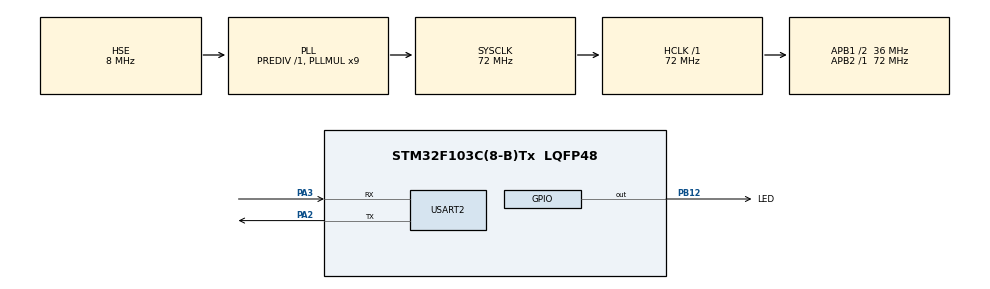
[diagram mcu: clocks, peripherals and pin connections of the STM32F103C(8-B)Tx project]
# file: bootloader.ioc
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IWDG.Prescaler=IWDG_PRESCALER_16
IWDG.Reload=2499
Mcu.Family=STM32F1
Mcu.Name=STM32F103C(8-B)Tx
Mcu.Package=LQFP48
NVIC.PriorityGroup=NVIC_PRIORITYGROUP_4
NVIC.USART2_IRQn=true\:0\:0\:false\:false\:true\:true\:true\:true
PA13.Mode=Serial_Wire
PA13.Signal=SYS_JTMS-SWDIO
PA14.Mode=Serial_Wire
PA14.Signal=SYS_JTCK-SWCLK
PA2.Mode=Asynchronous
PA2.Signal=USART2_TX
PA3.Mode=Asynchronous
PA3.Signal=USART2_RX
PB12.GPIO_Label=LED
PB12.PinState=GPIO_PIN_SET
PB12.Signal=GPIO_Output
PD0-OSC_IN.Mode=HSE-External-Oscillator
PD0-OSC_IN.Signal=RCC_OSC_IN
PD1-OSC_OUT.Mode=HSE-External-Oscillator
PD1-OSC_OUT.Signal=RCC_OSC_OUT
ProjectManager.HeapSize=0x200
ProjectManager.StackSize=0x400
ProjectManager.TargetToolchain=MDK-ARM V5.32
RCC.AHBFreq_Value=72000000
RCC.APB1CLKDivider=RCC_HCLK_DIV2
RCC.APB1Freq_Value=36000000
RCC.APB1TimFreq_Value=72000000
RCC.APB2Freq_Value=72000000
RCC.APB2TimFreq_Value=72000000
RCC.HCLKFreq_Value=72000000
RCC.PLLMUL=RCC_PLL_MUL9
RCC.PLLSourceVirtual=RCC_PLLSOURCE_HSE
RCC.SYSCLKFreq_VALUE=72000000
RCC.SYSCLKSource=RCC_SYSCLKSOURCE_PLLCLK
RCC.USBFreq_Value=72000000
TIM1.Period=1000-1
TIM1.Prescaler=7200-1
USART2.VirtualMode=VM_ASYNC
VP_CRC_VS_CRC.Mode=CRC_Activate
VP_IWDG_VS_IWDG.Mode=IWDG_Activate
VP_TIM1_VS_ClockSourceINT.Mode=Internal
board=custom

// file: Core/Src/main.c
/* USER CODE BEGIN Header */
/**
  ******************************************************************************
  * @file           : main.c
  * @brief          : Main program body
  ******************************************************************************
  * @attention
  *
  * Copyright (c) 2026 STMicroelectronics.
  * All rights reserved.
  *
  * This software is licensed under terms that can be found in the LICENSE file
  * in the root directory of this software component.
  * If no LICENSE file comes with this software, it is provided AS-IS.
  *
  ******************************************************************************
  */
/* USER CODE END Header */
#include "main.h"
#include "crc.h"
#include "iwdg.h"
#include "tim.h"
#include "usart.h"
#include "gpio.h"

/* USER CODE BEGIN Includes */
#include "Mydef.h"
/* USER CODE END Includes */

void SystemClock_Config(void);

/* USER CODE BEGIN 0 */

static uint32_t APP_add = APP_RUN_BASE;
void Goto_APP (void){
	//创建函数指针
	typedef void(* Start_Goto)  (void);

	uint32_t Gotoadd;
	Start_Goto GOtoApp;

	//关中断
	__disable_irq();

	//获取向量地址(栈地址偏移一位)
	Gotoadd=*(__IO uint32_t*)(APP_add+4);
	GOtoApp=(Start_Goto)Gotoadd;

	//设置栈顶指针
	__set_MSP(*(__IO uint32_t*)APP_add);
	//重定向向量表
	SCB->VTOR=APP_add;
	//跳转APP
	/*从向量地址开始运行*/
	/*函数利用运行函数方式*/
	/*函数指针指向开始运行位置*/
	/*编译器转成汇编后会直接BL进APP向量表*/
	GOtoApp();

}

/* USER CODE END 0 */

int main(void)
{

  /* MCU Configuration--------------------------------------------------------*/

  /* Reset of all peripherals, Initializes the Flash interface and the Systick. */
  HAL_Init();

  /* Configure the system clock */
  SystemClock_Config();

  /* Initialize all configured peripherals */
  MX_GPIO_Init();
  MX_IWDG_Init();
  MX_TIM1_Init();
  MX_CRC_Init();
  MX_USART2_UART_Init();
  /* USER CODE BEGIN 2 */

  /*查看是否为看门狗复位*/
uint32_t is_iwdg = (__HAL_RCC_GET_FLAG(RCC_FLAG_IWDGRST) != 0U);

__HAL_RCC_CLEAR_RESET_FLAGS(); /*清除复位标志位*/

if (is_iwdg) {
	/* 写状态：当前槽和匹配源槽标坏，并查找另一个 0x09 回滚槽 */
	uint8_t rollback_slot = FlashManage_HandleWatchdogReset();

	/* 有可用版本：复制到一号槽，更新 APP_add 后跳转 */
	if (rollback_slot != 0xFFU) {
		FlashManage_CopyValidBackup(rollback_slot);
		APP_add = APP_RUN_BASE;
		Goto_APP();
	}

	/* 都无可用版本：保持安全模式 */
	TIM_LED_Start();
	__enable_irq();
} else {
	/* 检查状态是否有 VALID_BACKUP，有则复制、同步状态并更新 APP_add */
	uint8_t backup_slot = FlashManage_CheckValidBackup();

	if (backup_slot != 0xFFU) {
		FlashManage_CopyValidBackup(backup_slot);
		APP_add = APP_RUN_BASE;
	}

	Goto_APP();
}

  /* USER CODE END 2 */

  /* Infinite loop */
  while (1)
  {

    /* USER CODE BEGIN 3 */
      /*安全模式*/
    HAL_GPIO_WritePin(LED_GPIO_Port, LED_Pin, GPIO_PIN_RESET);  /* 亮 20 ms */
    Delay_ms(20);
    HAL_GPIO_WritePin(LED_GPIO_Port, LED_Pin, GPIO_PIN_SET);    /* 灭 */
    Delay_ms(200);
	HAL_IWDG_Refresh(&hiwdg);

	  /*预留不写*/

  }
  /* USER CODE END 3 */
}

void SystemClock_Config(void)
{
  RCC_OscInitTypeDef RCC_OscInitStruct = {0};
  RCC_ClkInitTypeDef RCC_ClkInitStruct = {0};

  /** Initializes the RCC Oscillators according to the specified parameters
  * in the RCC_OscInitTypeDef structure.
  */
  RCC_OscInitStruct.OscillatorType = RCC_OSCILLATORTYPE_LSI|RCC_OSCILLATORTYPE_HSE;
  RCC_OscInitStruct.HSEState = RCC_HSE_ON;
  RCC_OscInitStruct.HSEPredivValue = RCC_HSE_PREDIV_DIV1;
  RCC_OscInitStruct.HSIState = RCC_HSI_ON;
  RCC_OscInitStruct.LSIState = RCC_LSI_ON;
  RCC_OscInitStruct.PLL.PLLState = RCC_PLL_ON;
  RCC_OscInitStruct.PLL.PLLSource = RCC_PLLSOURCE_HSE;
  RCC_OscInitStruct.PLL.PLLMUL = RCC_PLL_MUL9;
  if (HAL_RCC_OscConfig(&RCC_OscInitStruct) != HAL_OK)
  {
    Error_Handler();
  }

  /** Initializes the CPU, AHB and APB buses clocks
  */
  RCC_ClkInitStruct.ClockType = RCC_CLOCKTYPE_HCLK|RCC_CLOCKTYPE_SYSCLK
                              |RCC_CLOCKTYPE_PCLK1|RCC_CLOCKTYPE_PCLK2;
  RCC_ClkInitStruct.SYSCLKSource = RCC_SYSCLKSOURCE_PLLCLK;
  RCC_ClkInitStruct.AHBCLKDivider = RCC_SYSCLK_DIV1;
  RCC_ClkInitStruct.APB1CLKDivider = RCC_HCLK_DIV2;
  RCC_ClkInitStruct.APB2CLKDivider = RCC_HCLK_DIV1;

  if (HAL_RCC_ClockConfig(&RCC_ClkInitStruct, FLASH_LATENCY_2) != HAL_OK)
  {
    Error_Handler();
  }
}

void Error_Handler(void)
{
  __disable_irq();
  while (1)
  {
  }
}
